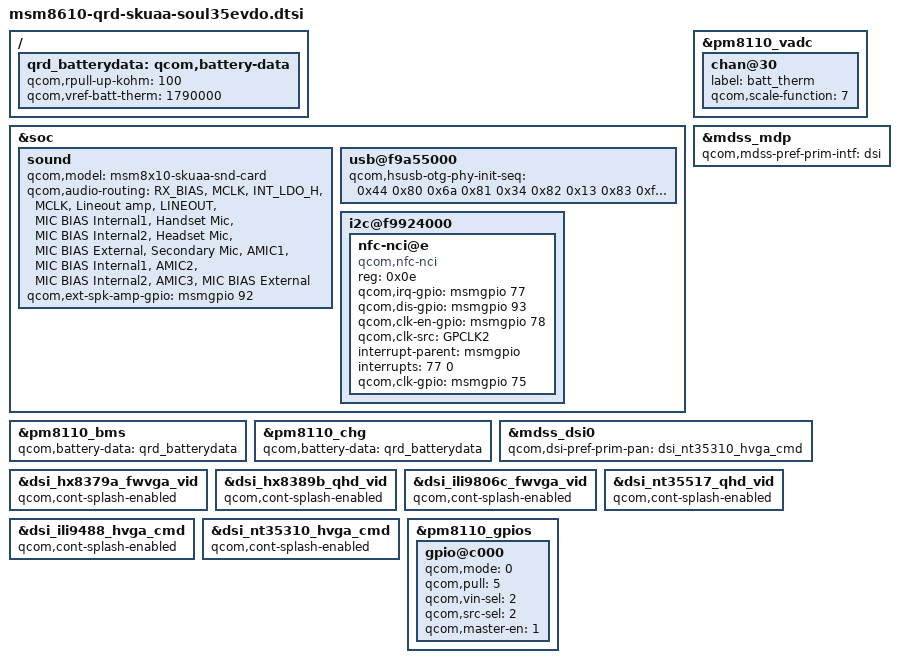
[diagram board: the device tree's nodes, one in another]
 /* Copyright (c) 2013, The Linux Foundation. All rights reserved.
 *
 * This program is free software; you can redistribute it and/or modify
 * it under the terms of the GNU General Public License version 2 and
 * only version 2 as published by the Free Software Foundation.
 *
 * This program is distributed in the hope that it will be useful,
 * but WITHOUT ANY WARRANTY; without even the implied warranty of
 * MERCHANTABILITY or FITNESS FOR A PARTICULAR PURPOSE.  See the
 * GNU General Public License for more details.
 */
/* [PLATFORM]-Mod-BEGIN by TCTSZ.zhoujinggao, 2014/03/26, rename the dtsi name for soul35 */
/include/ "msm8610-qrd-soul35evdo.dtsi"
/* [PLATFORM]-Mod-END by TCTSZ.zhoujinggao */
&soc {
    sound {
        qcom,model = "msm8x10-skuaa-snd-card";

        qcom,audio-routing =
            "RX_BIAS", "MCLK",
            "INT_LDO_H", "MCLK",
            "Lineout amp", "LINEOUT",
            "MIC BIAS Internal1", "Handset Mic",
            "MIC BIAS Internal2", "Headset Mic",
            "MIC BIAS External", "Secondary Mic",
            "AMIC1", "MIC BIAS Internal1",
            "AMIC2", "MIC BIAS Internal2",
            "AMIC3", "MIC BIAS External";

        qcom,ext-spk-amp-gpio = <&msmgpio 92 0x0>;
    };

	usb@f9a55000 {
		qcom,hsusb-otg-phy-init-seq =
		<0x44 0x80 0x6a 0x81 0x34 0x82 0x13 0x83 0xffffffff>;
	};

	i2c@f9924000 { /* BLSP-1 QUP-2 */
		nfc-nci@e {
			compatible = "qcom,nfc-nci";
			reg = <0x0e>;
			qcom,irq-gpio = <&msmgpio 77 0x00>;
			qcom,dis-gpio = <&msmgpio 93 0x00>;
			qcom,clk-en-gpio = <&msmgpio 78 0x00>;
			qcom,clk-src = "GPCLK2";
			interrupt-parent = <&msmgpio>;
			interrupts = <77 0>;
			qcom,clk-gpio = <&msmgpio 75 0x00>;
		};
	};
};

/ {
	qrd_batterydata: qcom,battery-data {
		qcom,rpull-up-kohm = <100>;
		qcom,vref-batt-therm = <1790000>;// [PLATFORM]-Mod by TCTSZ.cuiping.shi, for change adc vdd

		/include/ "batterydata-qrd-4v2-1300mah_F1.dtsi" /* change by shicuiping*/
		/include/ "batterydata-qrd-4v2-1300mah_F2.dtsi" /* change by shicuiping*/
	};

};

&pm8110_bms {
	status = "ok";
	qcom,battery-data = <&qrd_batterydata>;
};

&pm8110_chg {
	qcom,battery-data = <&qrd_batterydata>;
};

&pm8110_vadc {
	chan@30 {
		label = "batt_therm";
		qcom,scale-function = <7>;
	};
};

&mdss_mdp {
	qcom,mdss-pref-prim-intf = "dsi";
};

&mdss_dsi0 {
	qcom,dsi-pref-prim-pan = <&dsi_hx8379a_fwvga_vid>;
};

&dsi_hx8379a_fwvga_vid {
	qcom,cont-splash-enabled;
};

&mdss_dsi0 {
	qcom,dsi-pref-prim-pan = <&dsi_hx8389b_qhd_vid>;
};

&dsi_hx8389b_qhd_vid {
	qcom,cont-splash-enabled;
};

&mdss_dsi0 {
	qcom,dsi-pref-prim-pan = <&dsi_ili9806c_fwvga_vid>;
};

&dsi_ili9806c_fwvga_vid {
	qcom,cont-splash-enabled;
};

//leo add for second source panel baoqiang.qin@tcl.com
&mdss_dsi0 {
	qcom,dsi-pref-prim-pan = <&dsi_nt35517_qhd_vid>;
};

&dsi_nt35517_qhd_vid {
	qcom,cont-splash-enabled;
};
//leo add end for second source panel baoqiang.qin@tcl.com

//xiaopu.zhu add for ili9488-hvga-cmd
&mdss_dsi0 {
	qcom,dsi-pref-prim-pan = <&dsi_ili9488_hvga_cmd>;
};
&dsi_ili9488_hvga_cmd {
	qcom,cont-splash-enabled;
};
//xiaopu.zhu add for ili9488-hvga-cmd

//xiaopu.zhu add for nt35310-hvga-cmd
&mdss_dsi0 {
	qcom,dsi-pref-prim-pan = <&dsi_nt35310_hvga_cmd>;
};

&dsi_nt35310_hvga_cmd {
	qcom,cont-splash-enabled;
};
//xiaopu.zhu add for nt35510-hvga-cmd

&pm8110_gpios {
	gpio@c000 { /* GPIO 1 */
		qcom,mode = <0>;		/* QPNP_PIN_MODE_DIG_IN */
		qcom,pull = <5>;		/* QPNP_PIN_PULL_NO */
		qcom,vin-sel = <2>;		/* QPNP_PIN_VIN2 */
		qcom,src-sel = <2>;		/* QPNP_PIN_SEL_FUNC_1 */
		qcom,master-en = <1>;
	};
};
